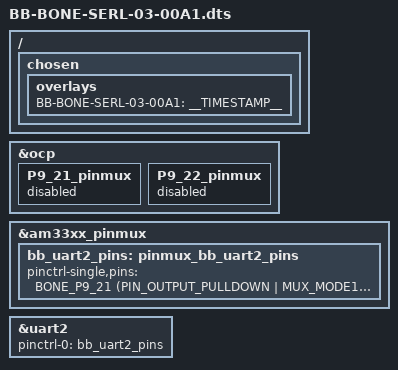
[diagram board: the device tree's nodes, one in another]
/*
 * Copyright (C) 2013 CircuitCo
 *
 * RS232 cape for the default configuration on UART2
 * Use one of the BB-UART* examples if you modify the default
 * configuration.
 *
 * This program is free software; you can redistribute it and/or modify
 * it under the terms of the GNU General Public License version 2 as
 * published by the Free Software Foundation.
 */

/dts-v1/;
/plugin/;

#include <dt-bindings/board/am335x-bbw-bbb-base.h>
#include <dt-bindings/pinctrl/am33xx.h>

/ {
	/*
	 * Helper to show loaded overlays under: /proc/device-tree/chosen/overlays/
	 */
	fragment@0 {
		target-path="/";
		__overlay__ {

			chosen {
				overlays {
					BB-BONE-SERL-03-00A1 = __TIMESTAMP__;
				};
			};
		};
	};

	/*
	 * Free up the pins used by the cape from the pinmux helpers.
	 */
	fragment@1 {
		target = <&ocp>;
		__overlay__ {
			P9_21_pinmux { status = "disabled"; };	/* P9_21: spi0_d0.uart2_txd */
			P9_22_pinmux { status = "disabled"; };	/* P9_22: spi0_sclk.uart2_rxd */
		};
	};

	fragment@2 {
		target = <&am33xx_pinmux>;
		__overlay__ {
			bb_uart2_pins: pinmux_bb_uart2_pins {
				pinctrl-single,pins = <
					BONE_P9_21 (PIN_OUTPUT_PULLDOWN | MUX_MODE1)	/* P9_21: spi0_d0.uart2_txd */
					BONE_P9_22 (PIN_INPUT_PULLUP | MUX_MODE1)	/* P9_22: spi0_sclk.uart2_rxd */
				>;
			};
		};
	};

	fragment@3 {
		target = <&uart2>;
		__overlay__ {
			status = "okay";
			pinctrl-names = "default";
			pinctrl-0 = <&bb_uart2_pins>;
		};
	};
};
